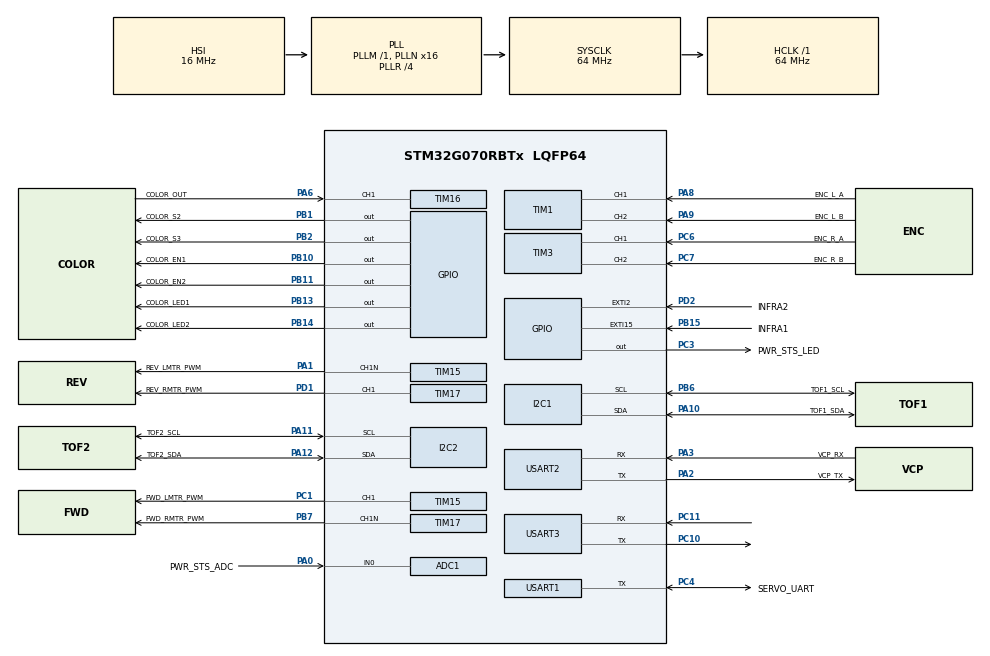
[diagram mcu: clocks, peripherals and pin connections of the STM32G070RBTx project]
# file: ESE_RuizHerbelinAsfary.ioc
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ADC1.Channel-2\#ChannelRegularConversion=ADC_CHANNEL_0
ADC1.NbrOfConversionFlag=1
ADC1.Rank-2\#ChannelRegularConversion=1
ADC1.SamplingTime-2\#ChannelRegularConversion=ADC_SAMPLINGTIME_COMMON_1
ADC1.SelectedChannel=ADC_CHANNEL_0
ADC1.master=1
I2C1.Timing=0x10707DBC
I2C2.Timing=0x10707DBC
Mcu.Family=STM32G0
Mcu.Name=STM32G070RBTx
Mcu.Package=LQFP64
NVIC.EXTI2_3_IRQn=true\:0\:0\:false\:false\:true\:true\:true\:true
NVIC.EXTI4_15_IRQn=true\:0\:0\:false\:false\:true\:true\:true\:true
PA0.GPIO_Label=PWR_STS_ADC
PA0.Mode=IN0
PA0.Signal=ADC1_IN0
PA1.GPIO_Label=REV_LMTR_PWM
PA1.Mode=PWM Generation1 CH1 CH1N
PA1.Signal=TIM15_CH1N
PA10.GPIO_Label=TOF1_SDA
PA10.Mode=I2C
PA10.Signal=I2C1_SDA
PA11\ [PA9].GPIO_Label=TOF2_SCL
PA11\ [PA9].Mode=I2C
PA11\ [PA9].Signal=I2C2_SCL
PA12\ [PA10].GPIO_Label=TOF2_SDA
PA12\ [PA10].Mode=I2C
PA12\ [PA10].Signal=I2C2_SDA
PA13.Mode=Serial_Wire
PA13.Signal=SYS_SWDIO
PA14-BOOT0.Mode=Serial_Wire
PA14-BOOT0.Signal=SYS_SWCLK
PA2.GPIO_Label=VCP_TX
PA2.Mode=Asynchronous
PA2.Signal=USART2_TX
PA3.GPIO_Label=VCP_RX
PA3.Mode=Asynchronous
PA3.Signal=USART2_RX
PA6.GPIO_Label=COLOR_OUT
PA6.Signal=S_TIM16_CH1
PA8.GPIO_Label=ENC_L_A
PA8.Signal=S_TIM1_CH1
PA9.GPIO_Label=ENC_L_B
PA9.Signal=S_TIM1_CH2
PB1.GPIO_Label=COLOR_S2
PB1.Signal=GPIO_Output
PB10.GPIO_Label=COLOR_EN1
PB10.Signal=GPIO_Output
PB11.GPIO_Label=COLOR_EN2
PB11.Signal=GPIO_Output
PB13.GPIO_Label=COLOR_LED1
PB13.Signal=GPIO_Output
PB14.GPIO_Label=COLOR_LED2
PB14.Signal=GPIO_Output
PB15.GPIO_Label=INFRA1
PB15.Signal=GPXTI15
PB2.GPIO_Label=COLOR_S3
PB2.Signal=GPIO_Output
PB6.GPIO_Label=TOF1_SCL
PB6.Mode=I2C
PB6.Signal=I2C1_SCL
PB7.GPIO_Label=FWD_RMTR_PWM
PB7.Mode=PWM Generation1 CH1 CH1N
PB7.Signal=TIM17_CH1N
PC1.GPIO_Label=FWD_LMTR_PWM
PC1.Signal=S_TIM15_CH1
PC10.Mode=Asynchronous
PC10.Signal=USART3_TX
PC11.Mode=Asynchronous
PC11.Signal=USART3_RX
PC3.GPIO_Label=PWR_STS_LED
PC3.Signal=GPIO_Output
PC4.GPIO_Label=SERVO_UART
PC4.Mode=Half_duplex(single_wire_mode)
PC4.Signal=USART1_TX
PC6.GPIO_Label=ENC_R_A
PC6.Signal=S_TIM3_CH1
PC7.GPIO_Label=ENC_R_B
PC7.Signal=S_TIM3_CH2
PD1.GPIO_Label=REV_RMTR_PWM
PD1.Signal=S_TIM17_CH1
PD2.GPIO_Label=INFRA2
PD2.Signal=GPXTI2
PF0-OSC_IN\ (PF0).Signal=RCC_OSC_IN
PF1-OSC_OUT\ (PF1).Signal=RCC_OSC_OUT
ProjectManager.HeapSize=0x200
ProjectManager.StackSize=0x400
ProjectManager.TargetToolchain=STM32CubeIDE
RCC.ADCFreq_Value=64000000
RCC.AHBFreq_Value=64000000
RCC.CortexFreq_Value=64000000
RCC.EXTERNAL_CLOCK_VALUE=48000
RCC.HCLKFreq_Value=64000000
RCC.HSE_VALUE=16000000
RCC.HSI_VALUE=16000000
RCC.LSE_VALUE=32768
RCC.PLLN=16
RCC.PLLR=RCC_PLLR_DIV4
RCC.SYSCLKFreq_VALUE=64000000
RCC.SYSCLKSource=RCC_SYSCLKSOURCE_PLLCLK
RCC.VCOOutputFreq_Value=256000000
SH.S_TIM15_CH1.0=TIM15_CH1,PWM Generation1 CH1 CH1N
SH.S_TIM16_CH1.0=TIM16_CH1,Input_Capture1_from_TI1
SH.S_TIM17_CH1.0=TIM17_CH1,PWM Generation1 CH1 CH1N
SH.S_TIM1_CH1.0=TIM1_CH1,Encoder_Interface
SH.S_TIM1_CH2.0=TIM1_CH2,Encoder_Interface
SH.S_TIM3_CH1.0=TIM3_CH1,Encoder_Interface
SH.S_TIM3_CH2.0=TIM3_CH2,Encoder_Interface
TIM1.EncoderMode=TIM_ENCODERMODE_TI12
TIM15.Channel-PWM\ Generation1\ CH1\ CH1N=TIM_CHANNEL_1
TIM16.Channel=TIM_CHANNEL_1
TIM17.Channel=TIM_CHANNEL_1
TIM3.EncoderMode=TIM_ENCODERMODE_TI12
USART1.BaudRate=1000000
USART1.VirtualMode-Half_duplex(single_wire_mode)=VM_ASYNC
USART2.VirtualMode-Asynchronous=VM_ASYNC
USART3.VirtualMode-Asynchronous=VM_ASYNC
VP_TIM15_VS_ClockSourceINT.Mode=Internal
VP_TIM16_VS_ClockSourceINT.Mode=Enable_Timer
VP_TIM17_VS_ClockSourceINT.Mode=Enable_Timer
board=custom

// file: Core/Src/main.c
/* USER CODE BEGIN Header */
/**
  ******************************************************************************
  * @file           : main.c
  * @brief          : Main program body
  ******************************************************************************
  * @attention
  *
  * Copyright (c) 2022 STMicroelectronics.
  * All rights reserved.
  *
  * This software is licensed under terms that can be found in the LICENSE file
  * in the root directory of this software component.
  * If no LICENSE file comes with this software, it is provided AS-IS.
  *
  ******************************************************************************
  * Pin Label :
  * 	TOFs:
  * 		- TOF1_SDA
  * 		- TOF1_SCL
  * 		- TOF2_SDA
  * 		- TOF2_SCL
  * 	Colors:
  * 		- COLOR_S2
  * 		- COLOR_S3
  * 		- COLOR_LED1
  * 		- COLOR_LED2
  * 		- COLOR_EN1
  * 		- COLOR_EN2
  * 		- COLOR_OUT
  * 	Infrarouge:
  * 		- INFRA1
  * 		- INFRA2
  * 	Servomotor:
  * 		- SERVO_UART
  * 	Encoder:
  * 		- ENC_R_A
  * 		- ENC_R_B
  * 		- ENC_L_A
  * 		- ENC_L_B
  * 	Motor:
  * 		- FWD_RMTR_PWM
  * 		- REV_RMTR_PWM
  * 		- FWD_LMTR_PWM
  * 		- REV_LMTR_PWM
  * 	VCP:
  * 		- VCP_TX
  * 		- VCP_RX
  * 	BATTERY STATUS:
  * 		- PWR_STS_ADC
  * 		- PWR_STS_LED
  ******************************************************************************
  */
/* USER CODE END Header */
#include "main.h"

ADC_HandleTypeDef hadc1;

I2C_HandleTypeDef hi2c1;
I2C_HandleTypeDef hi2c2;

TIM_HandleTypeDef htim1;
TIM_HandleTypeDef htim3;
TIM_HandleTypeDef htim15;
TIM_HandleTypeDef htim16;
TIM_HandleTypeDef htim17;

UART_HandleTypeDef huart1;
UART_HandleTypeDef huart2;
UART_HandleTypeDef huart3;

void SystemClock_Config(void);
static void MX_GPIO_Init(void);
static void MX_USART1_UART_Init(void);
static void MX_USART2_UART_Init(void);
static void MX_USART3_UART_Init(void);
static void MX_TIM1_Init(void);
static void MX_I2C1_Init(void);
static void MX_TIM3_Init(void);
static void MX_TIM15_Init(void);
static void MX_TIM16_Init(void);
static void MX_TIM17_Init(void);
static void MX_ADC1_Init(void);
static void MX_I2C2_Init(void);

int main(void)
{

  /* MCU Configuration--------------------------------------------------------*/

  /* Reset of all peripherals, Initializes the Flash interface and the Systick. */
  HAL_Init();

  /* Configure the system clock */
  SystemClock_Config();

  /* Initialize all configured peripherals */
  MX_GPIO_Init();
  MX_USART1_UART_Init();
  MX_USART2_UART_Init();
  MX_USART3_UART_Init();
  MX_TIM1_Init();
  MX_I2C1_Init();
  MX_TIM3_Init();
  MX_TIM15_Init();
  MX_TIM16_Init();
  MX_TIM17_Init();
  MX_ADC1_Init();
  MX_I2C2_Init();
  /* USER CODE BEGIN 2 */
  HAL_GPIO_WritePin(PWR_STS_LED_GPIO_Port,PWR_STS_LED_Pin,GPIO_PIN_SET);
  /* USER CODE END 2 */

  /* Infinite loop */
  /* USER CODE BEGIN WHILE */
  while (1)
  {
	  HAL_GPIO_TogglePin(PWR_STS_LED_GPIO_Port,PWR_STS_LED_Pin);
	  HAL_Delay(500);
    /* USER CODE END WHILE */

  }
}

void SystemClock_Config(void)
{
  RCC_OscInitTypeDef RCC_OscInitStruct = {0};
  RCC_ClkInitTypeDef RCC_ClkInitStruct = {0};

  /** Configure the main internal regulator output voltage
  */
  HAL_PWREx_ControlVoltageScaling(PWR_REGULATOR_VOLTAGE_SCALE1);

  /** Initializes the RCC Oscillators according to the specified parameters
  * in the RCC_OscInitTypeDef structure.
  */
  RCC_OscInitStruct.OscillatorType = RCC_OSCILLATORTYPE_HSI;
  RCC_OscInitStruct.HSIState = RCC_HSI_ON;
  RCC_OscInitStruct.HSIDiv = RCC_HSI_DIV1;
  RCC_OscInitStruct.HSICalibrationValue = RCC_HSICALIBRATION_DEFAULT;
  RCC_OscInitStruct.PLL.PLLState = RCC_PLL_ON;
  RCC_OscInitStruct.PLL.PLLSource = RCC_PLLSOURCE_HSI;
  RCC_OscInitStruct.PLL.PLLM = RCC_PLLM_DIV1;
  RCC_OscInitStruct.PLL.PLLN = 16;
  RCC_OscInitStruct.PLL.PLLP = RCC_PLLP_DIV2;
  RCC_OscInitStruct.PLL.PLLR = RCC_PLLR_DIV4;
  if (HAL_RCC_OscConfig(&RCC_OscInitStruct) != HAL_OK)
  {
    Error_Handler();
  }

  /** Initializes the CPU, AHB and APB buses clocks
  */
  RCC_ClkInitStruct.ClockType = RCC_CLOCKTYPE_HCLK|RCC_CLOCKTYPE_SYSCLK
                              |RCC_CLOCKTYPE_PCLK1;
  RCC_ClkInitStruct.SYSCLKSource = RCC_SYSCLKSOURCE_PLLCLK;
  RCC_ClkInitStruct.AHBCLKDivider = RCC_SYSCLK_DIV1;
  RCC_ClkInitStruct.APB1CLKDivider = RCC_HCLK_DIV1;

  if (HAL_RCC_ClockConfig(&RCC_ClkInitStruct, FLASH_LATENCY_2) != HAL_OK)
  {
    Error_Handler();
  }
}

static void MX_ADC1_Init(void)
{

  ADC_ChannelConfTypeDef sConfig = {0};

  /** Configure the global features of the ADC (Clock, Resolution, Data Alignment and number of conversion)
  */
  hadc1.Instance = ADC1;
  hadc1.Init.ClockPrescaler = ADC_CLOCK_SYNC_PCLK_DIV2;
  hadc1.Init.Resolution = ADC_RESOLUTION_12B;
  hadc1.Init.DataAlign = ADC_DATAALIGN_RIGHT;
  hadc1.Init.ScanConvMode = ADC_SCAN_DISABLE;
  hadc1.Init.EOCSelection = ADC_EOC_SINGLE_CONV;
  hadc1.Init.LowPowerAutoWait = DISABLE;
  hadc1.Init.LowPowerAutoPowerOff = DISABLE;
  hadc1.Init.ContinuousConvMode = DISABLE;
  hadc1.Init.NbrOfConversion = 1;
  hadc1.Init.DiscontinuousConvMode = DISABLE;
  hadc1.Init.ExternalTrigConv = ADC_SOFTWARE_START;
  hadc1.Init.ExternalTrigConvEdge = ADC_EXTERNALTRIGCONVEDGE_NONE;
  hadc1.Init.DMAContinuousRequests = DISABLE;
  hadc1.Init.Overrun = ADC_OVR_DATA_PRESERVED;
  hadc1.Init.SamplingTimeCommon1 = ADC_SAMPLETIME_1CYCLE_5;
  hadc1.Init.SamplingTimeCommon2 = ADC_SAMPLETIME_1CYCLE_5;
  hadc1.Init.OversamplingMode = DISABLE;
  hadc1.Init.TriggerFrequencyMode = ADC_TRIGGER_FREQ_HIGH;
  if (HAL_ADC_Init(&hadc1) != HAL_OK)
  {
    Error_Handler();
  }

  /** Configure Regular Channel
  */
  sConfig.Channel = ADC_CHANNEL_0;
  sConfig.Rank = ADC_REGULAR_RANK_1;
  sConfig.SamplingTime = ADC_SAMPLINGTIME_COMMON_1;
  if (HAL_ADC_ConfigChannel(&hadc1, &sConfig) != HAL_OK)
  {
    Error_Handler();
  }

}

static void MX_I2C1_Init(void)
{

  hi2c1.Instance = I2C1;
  hi2c1.Init.Timing = 0x10707DBC;
  hi2c1.Init.OwnAddress1 = 0;
  hi2c1.Init.AddressingMode = I2C_ADDRESSINGMODE_7BIT;
  hi2c1.Init.DualAddressMode = I2C_DUALADDRESS_DISABLE;
  hi2c1.Init.OwnAddress2 = 0;
  hi2c1.Init.OwnAddress2Masks = I2C_OA2_NOMASK;
  hi2c1.Init.GeneralCallMode = I2C_GENERALCALL_DISABLE;
  hi2c1.Init.NoStretchMode = I2C_NOSTRETCH_DISABLE;
  if (HAL_I2C_Init(&hi2c1) != HAL_OK)
  {
    Error_Handler();
  }

  /** Configure Analogue filter
  */
  if (HAL_I2CEx_ConfigAnalogFilter(&hi2c1, I2C_ANALOGFILTER_ENABLE) != HAL_OK)
  {
    Error_Handler();
  }

  /** Configure Digital filter
  */
  if (HAL_I2CEx_ConfigDigitalFilter(&hi2c1, 0) != HAL_OK)
  {
    Error_Handler();
  }

}

static void MX_I2C2_Init(void)
{

  hi2c2.Instance = I2C2;
  hi2c2.Init.Timing = 0x10707DBC;
  hi2c2.Init.OwnAddress1 = 0;
  hi2c2.Init.AddressingMode = I2C_ADDRESSINGMODE_7BIT;
  hi2c2.Init.DualAddressMode = I2C_DUALADDRESS_DISABLE;
  hi2c2.Init.OwnAddress2 = 0;
  hi2c2.Init.OwnAddress2Masks = I2C_OA2_NOMASK;
  hi2c2.Init.GeneralCallMode = I2C_GENERALCALL_DISABLE;
  hi2c2.Init.NoStretchMode = I2C_NOSTRETCH_DISABLE;
  if (HAL_I2C_Init(&hi2c2) != HAL_OK)
  {
    Error_Handler();
  }

  /** Configure Analogue filter
  */
  if (HAL_I2CEx_ConfigAnalogFilter(&hi2c2, I2C_ANALOGFILTER_ENABLE) != HAL_OK)
  {
    Error_Handler();
  }

  /** Configure Digital filter
  */
  if (HAL_I2CEx_ConfigDigitalFilter(&hi2c2, 0) != HAL_OK)
  {
    Error_Handler();
  }

}

static void MX_TIM1_Init(void)
{

  TIM_Encoder_InitTypeDef sConfig = {0};
  TIM_MasterConfigTypeDef sMasterConfig = {0};

  htim1.Instance = TIM1;
  htim1.Init.Prescaler = 0;
  htim1.Init.CounterMode = TIM_COUNTERMODE_UP;
  htim1.Init.Period = 65535;
  htim1.Init.ClockDivision = TIM_CLOCKDIVISION_DIV1;
  htim1.Init.RepetitionCounter = 0;
  htim1.Init.AutoReloadPreload = TIM_AUTORELOAD_PRELOAD_DISABLE;
  sConfig.EncoderMode = TIM_ENCODERMODE_TI12;
  sConfig.IC1Polarity = TIM_ICPOLARITY_RISING;
  sConfig.IC1Selection = TIM_ICSELECTION_DIRECTTI;
  sConfig.IC1Prescaler = TIM_ICPSC_DIV1;
  sConfig.IC1Filter = 0;
  sConfig.IC2Polarity = TIM_ICPOLARITY_RISING;
  sConfig.IC2Selection = TIM_ICSELECTION_DIRECTTI;
  sConfig.IC2Prescaler = TIM_ICPSC_DIV1;
  sConfig.IC2Filter = 0;
  if (HAL_TIM_Encoder_Init(&htim1, &sConfig) != HAL_OK)
  {
    Error_Handler();
  }
  sMasterConfig.MasterOutputTrigger = TIM_TRGO_RESET;
  sMasterConfig.MasterOutputTrigger2 = TIM_TRGO2_RESET;
  sMasterConfig.MasterSlaveMode = TIM_MASTERSLAVEMODE_DISABLE;
  if (HAL_TIMEx_MasterConfigSynchronization(&htim1, &sMasterConfig) != HAL_OK)
  {
    Error_Handler();
  }

}

static void MX_TIM3_Init(void)
{

  TIM_Encoder_InitTypeDef sConfig = {0};
  TIM_MasterConfigTypeDef sMasterConfig = {0};

  htim3.Instance = TIM3;
  htim3.Init.Prescaler = 0;
  htim3.Init.CounterMode = TIM_COUNTERMODE_UP;
  htim3.Init.Period = 65535;
  htim3.Init.ClockDivision = TIM_CLOCKDIVISION_DIV1;
  htim3.Init.AutoReloadPreload = TIM_AUTORELOAD_PRELOAD_DISABLE;
  sConfig.EncoderMode = TIM_ENCODERMODE_TI12;
  sConfig.IC1Polarity = TIM_ICPOLARITY_RISING;
  sConfig.IC1Selection = TIM_ICSELECTION_DIRECTTI;
  sConfig.IC1Prescaler = TIM_ICPSC_DIV1;
  sConfig.IC1Filter = 0;
  sConfig.IC2Polarity = TIM_ICPOLARITY_RISING;
  sConfig.IC2Selection = TIM_ICSELECTION_DIRECTTI;
  sConfig.IC2Prescaler = TIM_ICPSC_DIV1;
  sConfig.IC2Filter = 0;
  if (HAL_TIM_Encoder_Init(&htim3, &sConfig) != HAL_OK)
  {
    Error_Handler();
  }
  sMasterConfig.MasterOutputTrigger = TIM_TRGO_RESET;
  sMasterConfig.MasterSlaveMode = TIM_MASTERSLAVEMODE_DISABLE;
  if (HAL_TIMEx_MasterConfigSynchronization(&htim3, &sMasterConfig) != HAL_OK)
  {
    Error_Handler();
  }

}

static void MX_TIM15_Init(void)
{

  TIM_ClockConfigTypeDef sClockSourceConfig = {0};
  TIM_MasterConfigTypeDef sMasterConfig = {0};
  TIM_OC_InitTypeDef sConfigOC = {0};
  TIM_BreakDeadTimeConfigTypeDef sBreakDeadTimeConfig = {0};

  htim15.Instance = TIM15;
  htim15.Init.Prescaler = 0;
  htim15.Init.CounterMode = TIM_COUNTERMODE_UP;
  htim15.Init.Period = 65535;
  htim15.Init.ClockDivision = TIM_CLOCKDIVISION_DIV1;
  htim15.Init.RepetitionCounter = 0;
  htim15.Init.AutoReloadPreload = TIM_AUTORELOAD_PRELOAD_DISABLE;
  if (HAL_TIM_Base_Init(&htim15) != HAL_OK)
  {
    Error_Handler();
  }
  sClockSourceConfig.ClockSource = TIM_CLOCKSOURCE_INTERNAL;
  if (HAL_TIM_ConfigClockSource(&htim15, &sClockSourceConfig) != HAL_OK)
  {
    Error_Handler();
  }
  if (HAL_TIM_PWM_Init(&htim15) != HAL_OK)
  {
    Error_Handler();
  }
  sMasterConfig.MasterOutputTrigger = TIM_TRGO_RESET;
  sMasterConfig.MasterSlaveMode = TIM_MASTERSLAVEMODE_DISABLE;
  if (HAL_TIMEx_MasterConfigSynchronization(&htim15, &sMasterConfig) != HAL_OK)
  {
    Error_Handler();
  }
  sConfigOC.OCMode = TIM_OCMODE_PWM1;
  sConfigOC.Pulse = 0;
  sConfigOC.OCPolarity = TIM_OCPOLARITY_HIGH;
  sConfigOC.OCNPolarity = TIM_OCNPOLARITY_HIGH;
  sConfigOC.OCFastMode = TIM_OCFAST_DISABLE;
  sConfigOC.OCIdleState = TIM_OCIDLESTATE_RESET;
  sConfigOC.OCNIdleState = TIM_OCNIDLESTATE_RESET;
  if (HAL_TIM_PWM_ConfigChannel(&htim15, &sConfigOC, TIM_CHANNEL_1) != HAL_OK)
  {
    Error_Handler();
  }
  sBreakDeadTimeConfig.OffStateRunMode = TIM_OSSR_DISABLE;
  sBreakDeadTimeConfig.OffStateIDLEMode = TIM_OSSI_DISABLE;
  sBreakDeadTimeConfig.LockLevel = TIM_LOCKLEVEL_OFF;
  sBreakDeadTimeConfig.DeadTime = 0;
  sBreakDeadTimeConfig.BreakState = TIM_BREAK_DISABLE;
  sBreakDeadTimeConfig.BreakPolarity = TIM_BREAKPOLARITY_HIGH;
  sBreakDeadTimeConfig.BreakFilter = 0;
  sBreakDeadTimeConfig.AutomaticOutput = TIM_AUTOMATICOUTPUT_DISABLE;
  if (HAL_TIMEx_ConfigBreakDeadTime(&htim15, &sBreakDeadTimeConfig) != HAL_OK)
  {
    Error_Handler();
  }
  HAL_TIM_MspPostInit(&htim15);

}

static void MX_TIM16_Init(void)
{

  TIM_IC_InitTypeDef sConfigIC = {0};

  htim16.Instance = TIM16;
  htim16.Init.Prescaler = 0;
  htim16.Init.CounterMode = TIM_COUNTERMODE_UP;
  htim16.Init.Period = 65535;
  htim16.Init.ClockDivision = TIM_CLOCKDIVISION_DIV1;
  htim16.Init.RepetitionCounter = 0;
  htim16.Init.AutoReloadPreload = TIM_AUTORELOAD_PRELOAD_DISABLE;
  if (HAL_TIM_Base_Init(&htim16) != HAL_OK)
  {
    Error_Handler();
  }
  if (HAL_TIM_IC_Init(&htim16) != HAL_OK)
  {
    Error_Handler();
  }
  sConfigIC.ICPolarity = TIM_INPUTCHANNELPOLARITY_RISING;
  sConfigIC.ICSelection = TIM_ICSELECTION_DIRECTTI;
  sConfigIC.ICPrescaler = TIM_ICPSC_DIV1;
  sConfigIC.ICFilter = 0;
  if (HAL_TIM_IC_ConfigChannel(&htim16, &sConfigIC, TIM_CHANNEL_1) != HAL_OK)
  {
    Error_Handler();
  }

}

static void MX_TIM17_Init(void)
{

  TIM_OC_InitTypeDef sConfigOC = {0};
  TIM_BreakDeadTimeConfigTypeDef sBreakDeadTimeConfig = {0};

  htim17.Instance = TIM17;
  htim17.Init.Prescaler = 0;
  htim17.Init.CounterMode = TIM_COUNTERMODE_UP;
  htim17.Init.Period = 65535;
  htim17.Init.ClockDivision = TIM_CLOCKDIVISION_DIV1;
  htim17.Init.RepetitionCounter = 0;
  htim17.Init.AutoReloadPreload = TIM_AUTORELOAD_PRELOAD_DISABLE;
  if (HAL_TIM_Base_Init(&htim17) != HAL_OK)
  {
    Error_Handler();
  }
  if (HAL_TIM_PWM_Init(&htim17) != HAL_OK)
  {
    Error_Handler();
  }
  sConfigOC.OCMode = TIM_OCMODE_PWM1;
  sConfigOC.Pulse = 0;
  sConfigOC.OCPolarity = TIM_OCPOLARITY_HIGH;
  sConfigOC.OCNPolarity = TIM_OCNPOLARITY_HIGH;
  sConfigOC.OCFastMode = TIM_OCFAST_DISABLE;
  sConfigOC.OCIdleState = TIM_OCIDLESTATE_RESET;
  sConfigOC.OCNIdleState = TIM_OCNIDLESTATE_RESET;
  if (HAL_TIM_PWM_ConfigChannel(&htim17, &sConfigOC, TIM_CHANNEL_1) != HAL_OK)
  {
    Error_Handler();
  }
  sBreakDeadTimeConfig.OffStateRunMode = TIM_OSSR_DISABLE;
  sBreakDeadTimeConfig.OffStateIDLEMode = TIM_OSSI_DISABLE;
  sBreakDeadTimeConfig.LockLevel = TIM_LOCKLEVEL_OFF;
  sBreakDeadTimeConfig.DeadTime = 0;
  sBreakDeadTimeConfig.BreakState = TIM_BREAK_DISABLE;
  sBreakDeadTimeConfig.BreakPolarity = TIM_BREAKPOLARITY_HIGH;
  sBreakDeadTimeConfig.BreakFilter = 0;
  sBreakDeadTimeConfig.AutomaticOutput = TIM_AUTOMATICOUTPUT_DISABLE;
  if (HAL_TIMEx_ConfigBreakDeadTime(&htim17, &sBreakDeadTimeConfig) != HAL_OK)
  {
    Error_Handler();
  }
  HAL_TIM_MspPostInit(&htim17);

}

static void MX_USART1_UART_Init(void)
{

  huart1.Instance = USART1;
  huart1.Init.BaudRate = 1000000;
  huart1.Init.WordLength = UART_WORDLENGTH_8B;
  huart1.Init.StopBits = UART_STOPBITS_1;
  huart1.Init.Parity = UART_PARITY_NONE;
  huart1.Init.Mode = UART_MODE_TX_RX;
  huart1.Init.HwFlowCtl = UART_HWCONTROL_NONE;
  huart1.Init.OverSampling = UART_OVERSAMPLING_16;
  huart1.Init.OneBitSampling = UART_ONE_BIT_SAMPLE_DISABLE;
  huart1.Init.ClockPrescaler = UART_PRESCALER_DIV1;
  huart1.AdvancedInit.AdvFeatureInit = UART_ADVFEATURE_NO_INIT;
  if (HAL_HalfDuplex_Init(&huart1) != HAL_OK)
  {
    Error_Handler();
  }
  if (HAL_UARTEx_SetTxFifoThreshold(&huart1, UART_TXFIFO_THRESHOLD_1_8) != HAL_OK)
  {
    Error_Handler();
  }
  if (HAL_UARTEx_SetRxFifoThreshold(&huart1, UART_RXFIFO_THRESHOLD_1_8) != HAL_OK)
  {
    Error_Handler();
  }
  if (HAL_UARTEx_DisableFifoMode(&huart1) != HAL_OK)
  {
    Error_Handler();
  }

}

static void MX_USART2_UART_Init(void)
{

  huart2.Instance = USART2;
  huart2.Init.BaudRate = 115200;
  huart2.Init.WordLength = UART_WORDLENGTH_8B;
  huart2.Init.StopBits = UART_STOPBITS_1;
  huart2.Init.Parity = UART_PARITY_NONE;
  huart2.Init.Mode = UART_MODE_TX_RX;
  huart2.Init.HwFlowCtl = UART_HWCONTROL_NONE;
  huart2.Init.OverSampling = UART_OVERSAMPLING_16;
  huart2.Init.OneBitSampling = UART_ONE_BIT_SAMPLE_DISABLE;
  huart2.Init.ClockPrescaler = UART_PRESCALER_DIV1;
  huart2.AdvancedInit.AdvFeatureInit = UART_ADVFEATURE_NO_INIT;
  if (HAL_UART_Init(&huart2) != HAL_OK)
  {
    Error_Handler();
  }
  if (HAL_UARTEx_SetTxFifoThreshold(&huart2, UART_TXFIFO_THRESHOLD_1_8) != HAL_OK)
  {
    Error_Handler();
  }
  if (HAL_UARTEx_SetRxFifoThreshold(&huart2, UART_RXFIFO_THRESHOLD_1_8) != HAL_OK)
  {
    Error_Handler();
  }
  if (HAL_UARTEx_DisableFifoMode(&huart2) != HAL_OK)
  {
    Error_Handler();
  }

}

static void MX_USART3_UART_Init(void)
{

  huart3.Instance = USART3;
  huart3.Init.BaudRate = 115200;
  huart3.Init.WordLength = UART_WORDLENGTH_8B;
  huart3.Init.StopBits = UART_STOPBITS_1;
  huart3.Init.Parity = UART_PARITY_NONE;
  huart3.Init.Mode = UART_MODE_TX_RX;
  huart3.Init.HwFlowCtl = UART_HWCONTROL_NONE;
  huart3.Init.OverSampling = UART_OVERSAMPLING_16;
  huart3.Init.OneBitSampling = UART_ONE_BIT_SAMPLE_DISABLE;
  huart3.Init.ClockPrescaler = UART_PRESCALER_DIV1;
  huart3.AdvancedInit.AdvFeatureInit = UART_ADVFEATURE_NO_INIT;
  if (HAL_UART_Init(&huart3) != HAL_OK)
  {
    Error_Handler();
  }

}

static void MX_GPIO_Init(void)
{
  GPIO_InitTypeDef GPIO_InitStruct = {0};

  /* GPIO Ports Clock Enable */
  __HAL_RCC_GPIOC_CLK_ENABLE();
  __HAL_RCC_GPIOF_CLK_ENABLE();
  __HAL_RCC_GPIOA_CLK_ENABLE();
  __HAL_RCC_GPIOB_CLK_ENABLE();
  __HAL_RCC_GPIOD_CLK_ENABLE();

  /*Configure GPIO pin Output Level */
  HAL_GPIO_WritePin(PWR_STS_LED_GPIO_Port, PWR_STS_LED_Pin, GPIO_PIN_RESET);

  /*Configure GPIO pin Output Level */
  HAL_GPIO_WritePin(GPIOB, COLOR_S2_Pin|COLOR_S3_Pin|COLOR_EN1_Pin|COLOR_EN2_Pin
                          |COLOR_LED1_Pin|COLOR_LED2_Pin, GPIO_PIN_RESET);

  /*Configure GPIO pin : PWR_STS_LED_Pin */
  GPIO_InitStruct.Pin = PWR_STS_LED_Pin;
  GPIO_InitStruct.Mode = GPIO_MODE_OUTPUT_PP;
  GPIO_InitStruct.Pull = GPIO_NOPULL;
  GPIO_InitStruct.Speed = GPIO_SPEED_FREQ_LOW;
  HAL_GPIO_Init(PWR_STS_LED_GPIO_Port, &GPIO_InitStruct);

  /*Configure GPIO pins : COLOR_S2_Pin COLOR_S3_Pin COLOR_EN1_Pin COLOR_EN2_Pin
                           COLOR_LED1_Pin COLOR_LED2_Pin */
  GPIO_InitStruct.Pin = COLOR_S2_Pin|COLOR_S3_Pin|COLOR_EN1_Pin|COLOR_EN2_Pin
                          |COLOR_LED1_Pin|COLOR_LED2_Pin;
  GPIO_InitStruct.Mode = GPIO_MODE_OUTPUT_PP;
  GPIO_InitStruct.Pull = GPIO_NOPULL;
  GPIO_InitStruct.Speed = GPIO_SPEED_FREQ_LOW;
  HAL_GPIO_Init(GPIOB, &GPIO_InitStruct);

  /*Configure GPIO pin : INFRA1_Pin */
  GPIO_InitStruct.Pin = INFRA1_Pin;
  GPIO_InitStruct.Mode = GPIO_MODE_IT_RISING;
  GPIO_InitStruct.Pull = GPIO_NOPULL;
  HAL_GPIO_Init(INFRA1_GPIO_Port, &GPIO_InitStruct);

  /*Configure GPIO pin : INFRA2_Pin */
  GPIO_InitStruct.Pin = INFRA2_Pin;
  GPIO_InitStruct.Mode = GPIO_MODE_IT_RISING;
  GPIO_InitStruct.Pull = GPIO_NOPULL;
  HAL_GPIO_Init(INFRA2_GPIO_Port, &GPIO_InitStruct);

  /* EXTI interrupt init*/
  HAL_NVIC_SetPriority(EXTI2_3_IRQn, 0, 0);
  HAL_NVIC_EnableIRQ(EXTI2_3_IRQn);

  HAL_NVIC_SetPriority(EXTI4_15_IRQn, 0, 0);
  HAL_NVIC_EnableIRQ(EXTI4_15_IRQn);

}

void Error_Handler(void)
{
  __disable_irq();
  while (1)
  {
  }
}
